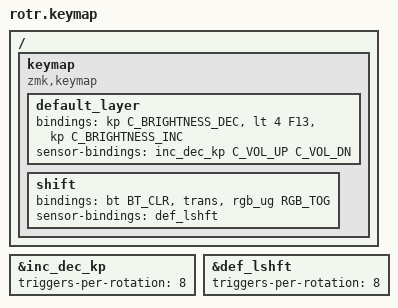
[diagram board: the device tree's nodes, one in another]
#include <behaviors.dtsi>
#include <dt-bindings/zmk/keys.h>
#include <dt-bindings/zmk/rgb.h>
#include <dt-bindings/zmk/bt.h>

&inc_dec_kp {
	triggers-per-rotation = <8>;
};
&def_lshft {
	triggers-per-rotation = <8>;
};

/ {
	keymap {
		compatible = "zmk,keymap";

		default_layer {
			//PREV | PLAY/PAUSE | NEXT
			bindings = <&kp C_BRIGHTNESS_DEC &lt 4 F13 &kp C_BRIGHTNESS_INC>;
			sensor-bindings = <&inc_dec_kp C_VOL_UP C_VOL_DN>;
		};
		shift {
			//PREV | PLAY/PAUSE | NEXT
			bindings = <&bt BT_CLR &trans &rgb_ug RGB_TOG>;
			sensor-bindings = <&def_lshft>;
		};
	};
};
